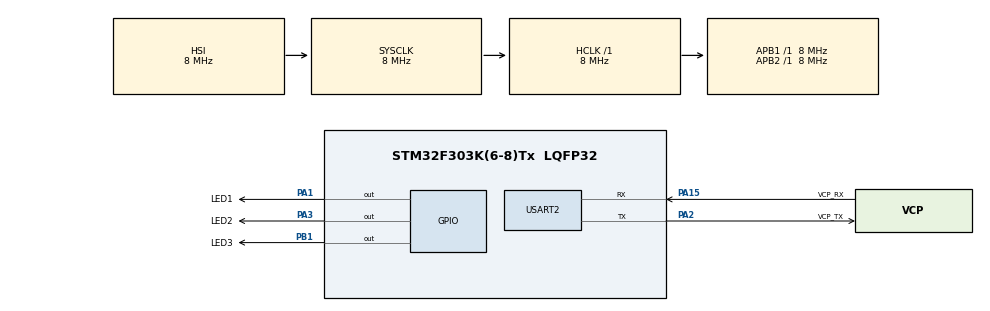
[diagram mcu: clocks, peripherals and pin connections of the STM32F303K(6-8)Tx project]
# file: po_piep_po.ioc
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Mcu.Family=STM32F3
Mcu.Name=STM32F303K(6-8)Tx
Mcu.Package=LQFP32
NVIC.PriorityGroup=NVIC_PRIORITYGROUP_4
PA1.GPIO_Label=LED1
PA1.Signal=GPIO_Output
PA13.GPIO_Label=SWDIO
PA13.Mode=Serial_Wire
PA13.Signal=SYS_JTMS-SWDIO
PA14.GPIO_Label=SWCLK
PA14.Mode=Serial_Wire
PA14.Signal=SYS_JTCK-SWCLK
PA15.GPIO_Label=VCP_RX
PA15.Mode=Asynchronous
PA15.Signal=USART2_RX
PA2.GPIO_Label=VCP_TX
PA2.Mode=Asynchronous
PA2.Signal=USART2_TX
PA3.GPIO_Label=LED2
PA3.Signal=GPIO_Output
PB1.GPIO_Label=LED3
PB1.Signal=GPIO_Output
PF0\ /\ OSC_IN.GPIO_Label=MCO
PF0\ /\ OSC_IN.Mode=HSE-External-Clock-Source
PF0\ /\ OSC_IN.Signal=RCC_OSC_IN
ProjectManager.HeapSize=0x200
ProjectManager.StackSize=0x400
ProjectManager.TargetToolchain=STM32CubeIDE
RCC.AHBFreq_Value=8000000
RCC.APB1Freq_Value=8000000
RCC.APB2Freq_Value=8000000
RCC.CortexFreq_Value=8000000
RCC.HSE_VALUE=8000000
RCC.HSI_VALUE=8000000
RCC.SYSCLKFreq_VALUE=8000000
USART2.VirtualMode-Asynchronous=VM_ASYNC
board=NUCLEO-F303K8

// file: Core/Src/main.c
/* USER CODE BEGIN Header */
/**
  ******************************************************************************
  * @file           : main.c
  * @brief          : Main program body
  ******************************************************************************
  * @attention
  *
  * Copyright (c) 2026 STMicroelectronics.
  * All rights reserved.
  *
  * This software is licensed under terms that can be found in the LICENSE file
  * in the root directory of this software component.
  * If no LICENSE file comes with this software, it is provided AS-IS.
  *
  ******************************************************************************
  */
/* USER CODE END Header */
#include "main.h"

UART_HandleTypeDef huart2;

void SystemClock_Config(void);
static void MX_GPIO_Init(void);
static void MX_USART2_UART_Init(void);

int main(void)
{

  /* MCU Configuration--------------------------------------------------------*/

  /* Reset of all peripherals, Initializes the Flash interface and the Systick. */
  HAL_Init();

  /* Configure the system clock */
  SystemClock_Config();

  /* Initialize all configured peripherals */
  MX_GPIO_Init();
  MX_USART2_UART_Init();
  /* USER CODE BEGIN 2 */
  uint32_t last1 = 0;
  uint32_t last2 = 0;
  /* USER CODE END 2 */

  /* Infinite loop */
  /* USER CODE BEGIN WHILE */
  while (1)
  {
	  uint32_t now = HAL_GetTick();

	  if((now - last1) >= 250){
	  HAL_GPIO_TogglePin(LED1_GPIO_Port, LED1_Pin);
	  last1 = now;
	  }

	  if((now - last2) >= 900){
	  	  HAL_GPIO_TogglePin(LED2_GPIO_Port, LED2_Pin);
	  	last2 = now;
	  }

	  HAL_GPIO_WritePin(LED3_GPIO_Port, LED3_Pin, !HAL_GPIO_ReadPin(SW3_GPIO_Port, SW3_Pin));

    /* USER CODE END WHILE */

  }
}

void SystemClock_Config(void)
{
  RCC_OscInitTypeDef RCC_OscInitStruct = {0};
  RCC_ClkInitTypeDef RCC_ClkInitStruct = {0};

  /** Initializes the RCC Oscillators according to the specified parameters
  * in the RCC_OscInitTypeDef structure.
  */
  RCC_OscInitStruct.OscillatorType = RCC_OSCILLATORTYPE_HSI;
  RCC_OscInitStruct.HSIState = RCC_HSI_ON;
  RCC_OscInitStruct.HSICalibrationValue = RCC_HSICALIBRATION_DEFAULT;
  RCC_OscInitStruct.PLL.PLLState = RCC_PLL_NONE;
  if (HAL_RCC_OscConfig(&RCC_OscInitStruct) != HAL_OK)
  {
    Error_Handler();
  }

  /** Initializes the CPU, AHB and APB buses clocks
  */
  RCC_ClkInitStruct.ClockType = RCC_CLOCKTYPE_HCLK|RCC_CLOCKTYPE_SYSCLK
                              |RCC_CLOCKTYPE_PCLK1|RCC_CLOCKTYPE_PCLK2;
  RCC_ClkInitStruct.SYSCLKSource = RCC_SYSCLKSOURCE_HSI;
  RCC_ClkInitStruct.AHBCLKDivider = RCC_SYSCLK_DIV1;
  RCC_ClkInitStruct.APB1CLKDivider = RCC_HCLK_DIV1;
  RCC_ClkInitStruct.APB2CLKDivider = RCC_HCLK_DIV1;

  if (HAL_RCC_ClockConfig(&RCC_ClkInitStruct, FLASH_LATENCY_0) != HAL_OK)
  {
    Error_Handler();
  }
}

static void MX_USART2_UART_Init(void)
{

  huart2.Instance = USART2;
  huart2.Init.BaudRate = 115200;
  huart2.Init.WordLength = UART_WORDLENGTH_8B;
  huart2.Init.StopBits = UART_STOPBITS_1;
  huart2.Init.Parity = UART_PARITY_NONE;
  huart2.Init.Mode = UART_MODE_TX_RX;
  huart2.Init.HwFlowCtl = UART_HWCONTROL_NONE;
  huart2.Init.OverSampling = UART_OVERSAMPLING_16;
  huart2.Init.OneBitSampling = UART_ONE_BIT_SAMPLE_DISABLE;
  huart2.AdvancedInit.AdvFeatureInit = UART_ADVFEATURE_NO_INIT;
  if (HAL_UART_Init(&huart2) != HAL_OK)
  {
    Error_Handler();
  }

}

static void MX_GPIO_Init(void)
{
  GPIO_InitTypeDef GPIO_InitStruct = {0};

  /* GPIO Ports Clock Enable */
  __HAL_RCC_GPIOF_CLK_ENABLE();
  __HAL_RCC_GPIOA_CLK_ENABLE();
  __HAL_RCC_GPIOB_CLK_ENABLE();

  /*Configure GPIO pin Output Level */
  HAL_GPIO_WritePin(GPIOA, LED1_Pin|LED2_Pin, GPIO_PIN_RESET);

  /*Configure GPIO pin Output Level */
  HAL_GPIO_WritePin(LED3_GPIO_Port, LED3_Pin, GPIO_PIN_RESET);

  /*Configure GPIO pins : LED1_Pin LED2_Pin */
  GPIO_InitStruct.Pin = LED1_Pin|LED2_Pin;
  GPIO_InitStruct.Mode = GPIO_MODE_OUTPUT_PP;
  GPIO_InitStruct.Pull = GPIO_NOPULL;
  GPIO_InitStruct.Speed = GPIO_SPEED_FREQ_LOW;
  HAL_GPIO_Init(GPIOA, &GPIO_InitStruct);

  /*Configure GPIO pin : LED3_Pin */
  GPIO_InitStruct.Pin = LED3_Pin;
  GPIO_InitStruct.Mode = GPIO_MODE_OUTPUT_PP;
  GPIO_InitStruct.Pull = GPIO_NOPULL;
  GPIO_InitStruct.Speed = GPIO_SPEED_FREQ_LOW;
  HAL_GPIO_Init(LED3_GPIO_Port, &GPIO_InitStruct);

}

void Error_Handler(void)
{
  __disable_irq();
  while (1)
  {
  }
}
